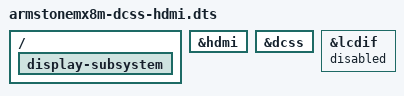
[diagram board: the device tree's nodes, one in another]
/*
* Copyright (C) 2020 F&S Elektronik Systeme GmbH
*
* This program is free software; you can redistribute it and/or modify
* it under the terms of the GNU General Public License version 2 as
* published by the Free Software Foundation.
*/

#include "armstonemx8m.dts"

/{
	display-subsystem {
		status = "okay";
	};
};


&hdmi {
	status = "okay";
};

&dcss {
	status = "okay";
};

&lcdif {
	status = "disabled";
};
